# CY8C5888LTI_LP097 register map
File version: 0.1
CY8C58LP
Registers are 8-bit, read-write, no defined reset value unless marked. A register's access mark holds for its fields unless they carry their own. Offsets are from the block's base; lines under a group give offsets from that group; [hi:lo] are bit positions; {n}, {i} and the like mark numbered series; 'fields as' and 'values as' point back to an identical list; <NAME> marks a mode.

## Memory map
0x00000000 sigBuf
0x00000000 USBUART — USBFS
0x00000000 BLE_UART — UART
0x00000000 pwmSAMPLING
0x00000000 IDAC8_3
0x00000000 IDAC8_2
0x00000000 IDAC8_4
0x00000000 ADC_SAR_1 — SAR ADC
0x00000000 ADC_SAR_2 — SAR ADC
0x00000000 Track_Hold_2
0x00000000 Track_Hold_1
0x00000000 CompTrigger
0x00000000 IDAC8_1
0x00000000 UART_1 — UART
0x00000000 refOut
0x40006473 internTrigger

## sigBuf
Base 0x00000000
0x400043A4 PM_ACT_CFG4 — Active Power Mode Configuration Register 4
  [3:0] EN_OPAMP — Enables subsystems during active power mode
    0=Blk_0 (Enables analog linear output buffer for Opamp block 0); 2=Blk_1 (Enables analog linear output buffer for Opamp block 1); 4=Blk_2 (Enables analog linear output buffer for Opamp block 2); 8=Blk_3 (Enables analog linear output buffer for Opamp block 3)
0x400043B4 PM_STBY_CFG4 — Standby Power Mode Configuration Register 4
  [3:0] EN_OPAMP — Enables subsystems during standby power mode
    values as PM_ACT_CFG4.EN_OPAMP
0x40004624 OPAMP__TR0 — Analog Output Buffer Trim Register 0
  [4:0] offset_trim — Offset Trim: 420uV typical step size; +/- 6.8mV offset trimmable range
0x40004625 OPAMP__TR1 — Analog Output Buffer Trim Register 1
0x4000585C OPAMP__CR — Analog Output Buffer Configuration Register
  [1:0] pwr_mode — Power Mode
    0=Default_Fast (Default Power mode Fast); 1=Slow (Power Mode Slow); 2=Medium (Power Mode Medium); 3=Fast (Power Mode Fast)
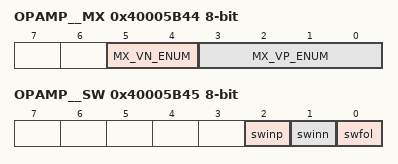
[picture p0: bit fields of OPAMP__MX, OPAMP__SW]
0x40005B44 OPAMP__MX — Analog Buffer Input Selection Register
  [5:4] MX_VN_ENUM — MUX select VN (Negative terminal input)
    0=OPAMP0_MX_VN_DEFAULT (Default - Not Connected (NC)); 1=OPAMP0_MX_VN_AG4 (MUX Selection AGL(4)); 2=OPAMP0_MX_VN_AG6 (MUX Selection AGL(6)); 3=OPAMP0_MX_VN_0x3 (Reserved (NC))
  [3:0] MX_VP_ENUM — MUX select VP (Positive terminal input)
    0=OPAMP0_MX_VP_DEFAULT (Default - Not Connected (NC)); {v}=OPAMP0_MX_VP_AG{v+3} (MUX Selection AGL({v+3})) (v=1..4); {v}=OPAMP0_MX_VP_ABUS{v-5} (MUX Selection ABUSL({v-5})) (v=5..8); 9=OPAMP0_MX_VP_VREF (MUX Selection: OPAMP Voltage Reference); {v}=OPAMP0_MX_VP_H_{0x0+v} (Reserved (NC)) (v=10..15)
0x40005B45 OPAMP__SW — Analog Buffer Routing Switch Register
  [2] swinp — Switch Enable Positive Input
  [1] swinn — Switch Enable Negative Input
  [0] swfol — Switch Enable Follow

## internTrigger
Base 0x40006473
0x00 internTrigger_CONTROL_REG

## BLE_UART — UART
Base 0x00000000
0x40006428 RX_BLE_UART_RX_ADDRESS1 — RX Address1 Register
0x40006438 RX_BLE_UART_RX_ADDRESS2 — RX Address2 Register
0x40006448 RX_BLE_UART_RX_DATA — RX Data Register
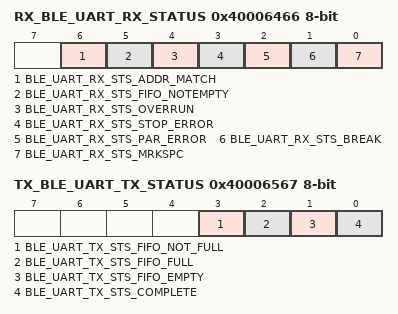
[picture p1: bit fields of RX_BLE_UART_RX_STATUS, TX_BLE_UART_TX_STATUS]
0x40006466 RX_BLE_UART_RX_STATUS — RX status register
  [6] BLE_UART_RX_STS_ADDR_MATCH ro, [5] BLE_UART_RX_STS_FIFO_NOTEMPTY ro, [4] BLE_UART_RX_STS_OVERRUN ro, [3] BLE_UART_RX_STS_STOP_ERROR ro, [2] BLE_UART_RX_STS_PAR_ERROR ro, [1] BLE_UART_RX_STS_BREAK ro, [0] BLE_UART_RX_STS_MRKSPC ro
0x40006544 TX_BLE_UART_TX_DATA — TX Data Register
0x40006567 TX_BLE_UART_TX_STATUS — TX status register
  [3] BLE_UART_TX_STS_FIFO_NOT_FULL ro, [2] BLE_UART_TX_STS_FIFO_FULL ro, [1] BLE_UART_TX_STS_FIFO_EMPTY ro, [0] BLE_UART_TX_STS_COMPLETE ro

## pwmSAMPLING
Base 0x00000000
0x400043A3 pwmSAMPLING_GLOBAL_ENABLE — PM.ACT.CFG
  [3:0] en_timer — Enable timer/counters.
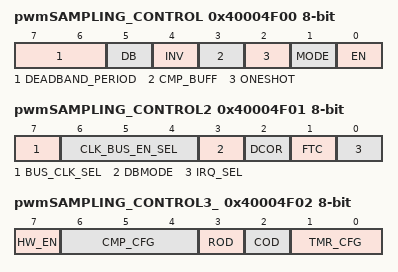
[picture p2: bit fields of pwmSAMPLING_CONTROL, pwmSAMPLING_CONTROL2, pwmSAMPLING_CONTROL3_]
0x40004F00 pwmSAMPLING_CONTROL — TMRx.CFG0
  [7:6] DEADBAND_PERIOD
  [5] DB — Deadband mode--Deadband phases phi1 and phi2 are outputted on CMP and TC output pins respectively.
    0=Timer (CMP and TC are output.); 1=Deadband (PHI1 (instead of CMP) and PHI2 (instead of TC) are output.)
  [4] INV — Invert sense of TIMEREN signal
  [3] CMP_BUFF — Buffer compare register. Compare register updates only on timer terminal count.
  [2] ONESHOT — Timer stops upon reaching stop condition defined by TMR_CFG bits. Can be restarted by asserting TIMER RESET or disabling and re-enabling block.
  [1] MODE — Mode. (0 = Timer; 1 = Comparator)
    0=Timer mode. CNT/CMP register holds timer count value.; 1=Comparator mode. CNT/CMP register holds comparator threshold value.
  [0] EN — Enables timer/comparator.
0x40004F01 pwmSAMPLING_CONTROL2 — TMRx.CFG1
  [7] BUS_CLK_SEL — Bus Clock selection.
  [6:4] CLK_BUS_EN_SEL — Digital Global Clock selection.
  [3] DBMODE — Deadband mode (asynchronous/synchronous). CMP output pin is also affected when not in deadband mode (CFG0.DEADBAND).
  [2] DCOR — Disable Clear on Read (DCOR) of Status Register SR0.
  [1] FTC — First Terminal Count (FTC). Setting this bit forces a single pulse on the TC pin when first enabled.
    0=Disable_FTC (Disable the single cycle pulse, which signifies the timer is starting.); 1=Enable_FTC (Enable the single cycle pulse, which signifies the timer is starting.)
  [0] IRQ_SEL — Irq selection. (0 = raw interrupts; 1 = status register interrupts)
0x40004F02 pwmSAMPLING_CONTROL3_ — TMRx.CFG2
  [7] HW_EN — When set Timer Enable controls counting.
  [6:4] CMP_CFG — Comparator configurations
    0=Equal (Compare Equal); 1=Less_than (Compare Less Than); 2=Less_than_or_equal (Compare Less Than or Equal .); 3=Greater (Compare Greater Than .); 4=Greater_than_or_equal (Compare Greater Than or Equal)
  [3] ROD — Reset On Disable (ROD). Resets internal state of output logic
  [2] COD — Clear On Disable (COD). Clears or gates outputs to zero.
  [1:0] TMR_CFG — Timer configuration (MODE = 0): 000 = Continuous; 001 = Pulsewidth; 010 = Period; 011 = Stop on IRQ
    0=Continuous (Timer runs while EN bit of CFG0 register is set to '1'.); 1=Pulsewidth (Timer runs from positive to negative edge of TIMEREN.); 2=Period (Timer runs from positive to positive edge of TIMEREN.); 3=Irq (Timer runs until IRQ.)
0x40004F04 pwmSAMPLING_PERIOD — TMRx.PER0 - Assigned Period
0x40004F06 pwmSAMPLING_COMPARE — TMRx.CNT_CMP0 - Assigned Compare Value
